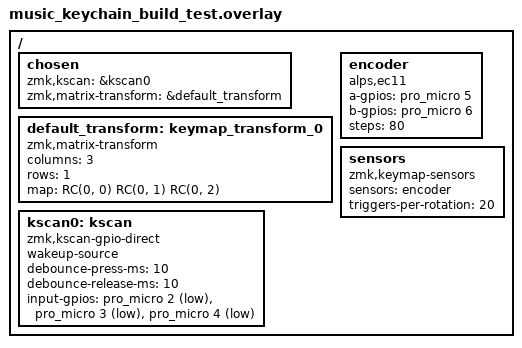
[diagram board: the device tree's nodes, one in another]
/*
 * COMPILE TEST ONLY -- THESE ARE NOT VERIFIED WIRING ASSIGNMENTS.
 *
 * These arbitrary logical Pro Micro positions exist only so ZMK can compile
 * the complete structure before the actual board and pins are known.
 */

#include <dt-bindings/zmk/matrix_transform.h>

/ {
    chosen {
        zmk,kscan = &kscan0;
        zmk,matrix-transform = &default_transform;
    };

    default_transform: keymap_transform_0 {
        compatible = "zmk,matrix-transform";
        columns = <3>;
        rows = <1>;
        map = <RC(0, 0) RC(0, 1) RC(0, 2)>;
    };

    kscan0: kscan {
        compatible = "zmk,kscan-gpio-direct";
        wakeup-source;
        debounce-press-ms = <10>;
        debounce-release-ms = <10>;
        input-gpios
            = <&pro_micro 2 (GPIO_ACTIVE_LOW | GPIO_PULL_UP)> /* TEMP previous */
            , <&pro_micro 3 (GPIO_ACTIVE_LOW | GPIO_PULL_UP)> /* TEMP play/pause */
            , <&pro_micro 4 (GPIO_ACTIVE_LOW | GPIO_PULL_UP)> /* TEMP next */
            ;
    };

    encoder: encoder {
        compatible = "alps,ec11";
        a-gpios = <&pro_micro 5 (GPIO_ACTIVE_HIGH | GPIO_PULL_UP)>; /* TEMP */
        b-gpios = <&pro_micro 6 (GPIO_ACTIVE_HIGH | GPIO_PULL_UP)>; /* TEMP */
        steps = <80>;
        status = "okay";
    };

    sensors: sensors {
        compatible = "zmk,keymap-sensors";
        sensors = <&encoder>;
        triggers-per-rotation = <20>;
    };
};

